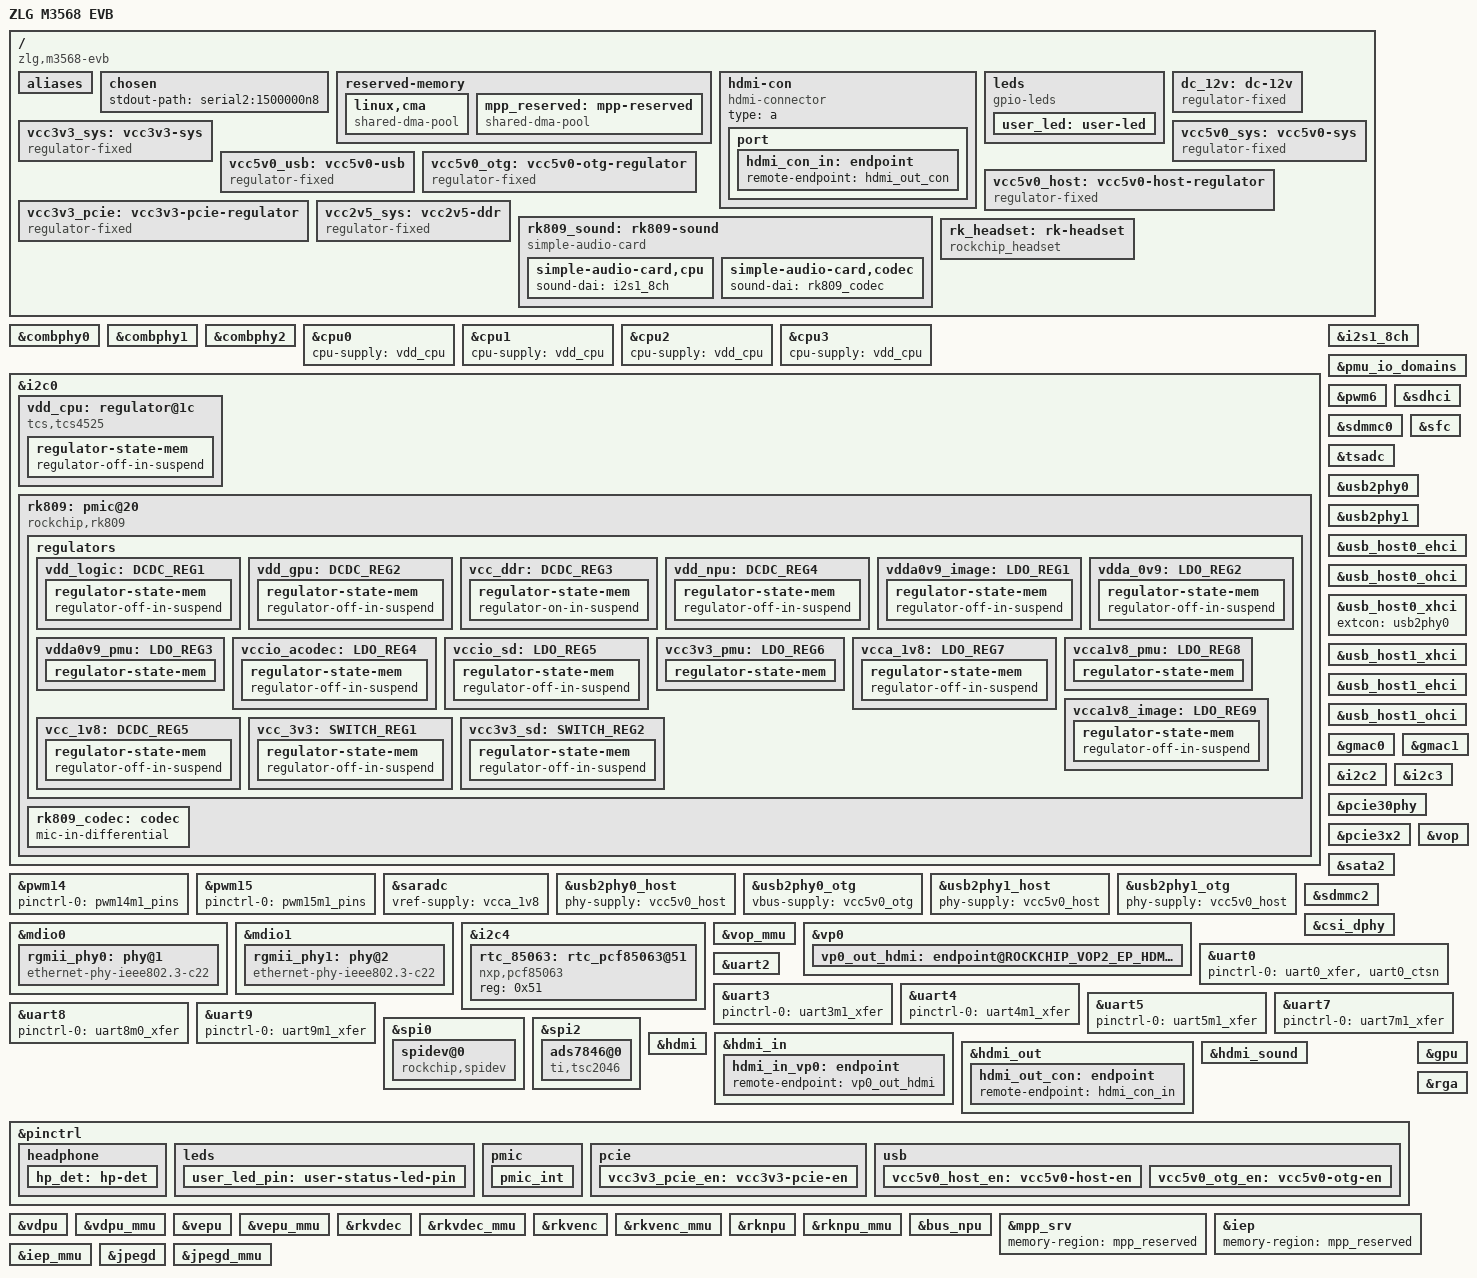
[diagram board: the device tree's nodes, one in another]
// SPDX-License-Identifier: (GPL-2.0+ OR MIT)
/*
 * Copyright (c) 2020 Rockchip Electronics Co., Ltd.
 * Copyright (c) 2025 Lemon1151 <smile1151@foxmail.com>
 *
 */

/dts-v1/;

#include <dt-bindings/gpio/gpio.h>
#include <dt-bindings/pwm/pwm.h>
#include <dt-bindings/leds/common.h>
#include <dt-bindings/input/input.h>
#include <dt-bindings/pinctrl/rockchip.h>
#include <dt-bindings/soc/rockchip,vop2.h>
#include "rk3568.dtsi"
#include "rk3568-vngpu.dtsi"
#include "rk3568-vngpu-rk809.dtsi"

/ {
	model = "ZLG M3568 EVB";
	compatible = "zlg,m3568-evb", "rockchip,rk3568";
	bootargs = "earlycon=uart8250,mmio32,0xfe660000 console=ttyFIQ0";
	
	aliases {
		ethernet0 = &gmac1;
		ethernet1 = &gmac0;
		mmc0 = &sdhci;
		mmc1 = &sdmmc0;
	};

  	chosen: chosen {
    		stdout-path = "serial2:1500000n8";
  	};

	reserved-memory {
		#address-cells = <2>;
		#size-cells = <2>;
		ranges;

		linux,cma {
			compatible = "shared-dma-pool";
			reusable;
			size = <0x0 0x10000000>; /* 256MB */
			linux,cma-default;
		};

		mpp_reserved: mpp-reserved {
			compatible = "shared-dma-pool";
			no-map;
			size = <0x0 0x8000000>; /* 128MB */
		};
	};

	hdmi-con {
		compatible = "hdmi-connector";
		type = "a";

		port {
			hdmi_con_in: endpoint {
				remote-endpoint = <&hdmi_out_con>;
			};
		};
	};

	leds: leds {
		compatible = "gpio-leds";
		user_led: user-led {
			label = "user_led";
			linux,default-trigger = "heartbeat";
			default-state = "on";
			gpios = <&gpio0 RK_PD6 GPIO_ACTIVE_HIGH>;
			pinctrl-names = "default";
			pinctrl-0 = <&user_led_pin>;
		};
	};

	dc_12v: dc-12v {
		compatible = "regulator-fixed";
		regulator-name = "dc_12v";
		regulator-always-on;
		regulator-boot-on;
		regulator-min-microvolt = <12000000>;
		regulator-max-microvolt = <12000000>;
	};

	vcc3v3_sys: vcc3v3-sys {
		compatible = "regulator-fixed";
		regulator-name = "vcc3v3_sys";
		regulator-always-on;
		regulator-boot-on;
		regulator-min-microvolt = <3300000>;
		regulator-max-microvolt = <3300000>;
		vin-supply = <&dc_12v>;
	};

	vcc5v0_sys: vcc5v0-sys {
		compatible = "regulator-fixed";
		regulator-name = "vcc5v0_sys";
		regulator-always-on;
		regulator-boot-on;
		regulator-min-microvolt = <5000000>;
		regulator-max-microvolt = <5000000>;
		vin-supply = <&dc_12v>;
	};

	vcc5v0_usb: vcc5v0-usb {
		compatible = "regulator-fixed";
		regulator-name = "vcc5v0_usb";
		regulator-always-on;
		regulator-boot-on;
		regulator-min-microvolt = <5000000>;
		regulator-max-microvolt = <5000000>;
		vin-supply = <&dc_12v>;
	};

	vcc5v0_host: vcc5v0-host-regulator {
		compatible = "regulator-fixed";
		regulator-name = "vcc5v0_host";
		regulator-boot-on;
		regulator-always-on;
		regulator-min-microvolt = <5000000>;
		regulator-max-microvolt = <5000000>;
		enable-active-high;
		gpio = <&gpio3 RK_PD5 GPIO_ACTIVE_HIGH>;
		vin-supply = <&vcc5v0_usb>;
		pinctrl-names = "default";
		pinctrl-0 = <&vcc5v0_host_en>;
	};

	vcc5v0_otg: vcc5v0-otg-regulator {
		compatible = "regulator-fixed";
		regulator-name = "vcc5v0_otg";
		regulator-min-microvolt = <5000000>;
		regulator-max-microvolt = <5000000>;
		enable-active-high;
		gpio = <&gpio4 RK_PB2 GPIO_ACTIVE_HIGH>;
		vin-supply = <&vcc5v0_usb>;
		pinctrl-names = "default";
		pinctrl-0 = <&vcc5v0_otg_en>;
	};

	vcc3v3_pcie: vcc3v3-pcie-regulator {
    		compatible = "regulator-fixed";
    		regulator-name = "vcc3v3_pcie";
    		regulator-min-microvolt = <3300000>;
    		regulator-max-microvolt = <3300000>;
    		gpio = <&gpio0 RK_PD4 GPIO_ACTIVE_HIGH>;
    		enable-active-high;
    		pinctrl-names = "default";
    		pinctrl-0 = <&vcc3v3_pcie_en>;
    		startup-delay-us = <10000>;
    		vin-supply = <&vcc5v0_sys>;
	};

	vcc2v5_sys: vcc2v5-ddr {
		compatible = "regulator-fixed";
		regulator-name = "vcc2v5-sys";
		regulator-always-on;
		regulator-boot-on;
		regulator-min-microvolt = <2500000>;
		regulator-max-microvolt = <2500000>;
		vin-supply = <&vcc3v3_sys>;
	};
	
	rk809_sound: rk809-sound {
		status = "okay";
		compatible = "simple-audio-card";
		simple-audio-card,format = "i2s";
		simple-audio-card,name = "rockchip,rk809-codec";
		simple-audio-card,mclk-fs = <256>;

		simple-audio-card,cpu {
			sound-dai = <&i2s1_8ch>;
		};
		simple-audio-card,codec {
			sound-dai = <&rk809_codec>;
		};
	};

	rk_headset: rk-headset {
		compatible = "rockchip_headset";
		headset_gpio = <&gpio1 RK_PB2 GPIO_ACTIVE_LOW>;
		pinctrl-names = "default";
		pinctrl-0 = <&hp_det>;
	};
};

&combphy0 {
	status = "okay";
};

&combphy1 {
	status = "okay";
};

&combphy2 {
	status = "okay";
};

&cpu0 {
	cpu-supply = <&vdd_cpu>;
};

&cpu1 {
	cpu-supply = <&vdd_cpu>;
};

&cpu2 {
	cpu-supply = <&vdd_cpu>;
};

&cpu3 {
	cpu-supply = <&vdd_cpu>;
};

&i2c0 {
	status = "okay";

	vdd_cpu: regulator@1c {
		compatible = "tcs,tcs4525";
		reg = <0x1c>;
		fcs,suspend-voltage-selector = <1>;
		regulator-name = "vdd_cpu";
		regulator-min-microvolt = <800000>;
		regulator-max-microvolt = <1150000>;
		regulator-ramp-delay = <2300>;
		regulator-always-on;
		regulator-boot-on;
		vin-supply = <&vcc5v0_sys>;

		regulator-state-mem {
			regulator-off-in-suspend;
		};
	};

	rk809: pmic@20 {
		compatible = "rockchip,rk809";
		reg = <0x20>;
		interrupt-parent = <&gpio0>;
		interrupts = <3 IRQ_TYPE_LEVEL_LOW>;
		#clock-cells = <1>;
		#sound-dai-cells = <0>;
		clock-output-names = "rk808-clkout1", "rk808-clkout2";
		pinctrl-names = "default";
		pinctrl-0 = <&pmic_int>;
		rockchip,system-power-controller;
		wakeup-source;

		vcc1-supply = <&vcc3v3_sys>;
		vcc2-supply = <&vcc3v3_sys>;
		vcc3-supply = <&vcc3v3_sys>;
		vcc4-supply = <&vcc3v3_sys>;
		vcc5-supply = <&vcc3v3_sys>;
		vcc6-supply = <&vcc3v3_sys>;
		vcc7-supply = <&vcc3v3_sys>;
		vcc8-supply = <&vcc3v3_sys>;
		vcc9-supply = <&vcc3v3_sys>;

		regulators {
			vdd_logic: DCDC_REG1 {
				regulator-always-on;
				regulator-boot-on;
				regulator-min-microvolt = <500000>;
				regulator-max-microvolt = <1350000>;
				regulator-init-microvolt = <900000>;
				regulator-ramp-delay = <6001>;
				regulator-initial-mode = <0x2>;
				regulator-name = "vdd_logic";
				regulator-state-mem {
					regulator-off-in-suspend;
				};
			};

			vdd_gpu: DCDC_REG2 {
				regulator-always-on;
				regulator-boot-on;
				regulator-min-microvolt = <500000>;
				regulator-max-microvolt = <1350000>;
				regulator-init-microvolt = <900000>;
				regulator-ramp-delay = <6001>;
				regulator-initial-mode = <0x2>;
				regulator-name = "vdd_gpu";
				regulator-state-mem {
					regulator-off-in-suspend;
				};
			};

			vcc_ddr: DCDC_REG3 {
				regulator-always-on;
				regulator-boot-on;
				regulator-initial-mode = <0x2>;
				regulator-name = "vcc_ddr";
				regulator-state-mem {
					regulator-on-in-suspend;
				};
			};

			vdd_npu: DCDC_REG4 {
				regulator-always-on;
				regulator-boot-on;
				regulator-min-microvolt = <500000>;
				regulator-max-microvolt = <1350000>;
				regulator-init-microvolt = <900000>;
				regulator-ramp-delay = <6001>;
				regulator-initial-mode = <0x2>;
				regulator-name = "vdd_npu";
				regulator-state-mem {
					regulator-off-in-suspend;
				};
			};

			vdda0v9_image: LDO_REG1 {
				regulator-boot-on;
				regulator-always-on;
				regulator-min-microvolt = <900000>;
				regulator-max-microvolt = <900000>;
				regulator-name = "vdda0v9_image";
				regulator-state-mem {
					regulator-off-in-suspend;
				};
			};

			vdda_0v9: LDO_REG2 {
				regulator-always-on;
				regulator-boot-on;
				regulator-min-microvolt = <900000>;
				regulator-max-microvolt = <900000>;
				regulator-name = "vdda_0v9";
				regulator-state-mem {
					regulator-off-in-suspend;
				};
			};

			vdda0v9_pmu: LDO_REG3 {
				regulator-always-on;
				regulator-boot-on;
				regulator-min-microvolt = <900000>;
				regulator-max-microvolt = <900000>;
				regulator-name = "vdda0v9_pmu";
				regulator-state-mem {
					regulator-on-in-suspend;
					regulator-suspend-microvolt = <900000>;
				};
			};

			vccio_acodec: LDO_REG4 {
				regulator-always-on;
				regulator-boot-on;
				regulator-min-microvolt = <3300000>;
				regulator-max-microvolt = <3300000>;
				regulator-name = "vccio_acodec";
				regulator-state-mem {
					regulator-off-in-suspend;
				};
			};

			vccio_sd: LDO_REG5 {
				regulator-always-on;
				regulator-boot-on;
				regulator-min-microvolt = <1800000>;
				regulator-max-microvolt = <3300000>;
				regulator-name = "vccio_sd";
				regulator-state-mem {
					regulator-off-in-suspend;
				};
			};

			vcc3v3_pmu: LDO_REG6 {
				regulator-always-on;
				regulator-boot-on;
				regulator-min-microvolt = <3300000>;
				regulator-max-microvolt = <3300000>;
				regulator-name = "vcc3v3_pmu";
				regulator-state-mem {
					regulator-on-in-suspend;
					regulator-suspend-microvolt = <3300000>;
				};
			};

			vcca_1v8: LDO_REG7 {
				regulator-always-on;
				regulator-boot-on;
				regulator-min-microvolt = <1800000>;
				regulator-max-microvolt = <1800000>;
				regulator-name = "vcca_1v8";
				regulator-state-mem {
					regulator-off-in-suspend;
				};
			};

			vcca1v8_pmu: LDO_REG8 {
				regulator-always-on;
				regulator-boot-on;
				regulator-min-microvolt = <1800000>;
				regulator-max-microvolt = <1800000>;
				regulator-name = "vcca1v8_pmu";
				regulator-state-mem {
					regulator-on-in-suspend;
					regulator-suspend-microvolt = <1800000>;
				};
			};

			vcca1v8_image: LDO_REG9 {
				regulator-always-on;
				regulator-boot-on;
				regulator-min-microvolt = <1800000>;
				regulator-max-microvolt = <1800000>;
				regulator-name = "vcca1v8_image";
				regulator-state-mem {
					regulator-off-in-suspend;
				};
			};

			vcc_1v8: DCDC_REG5 {
				regulator-always-on;
				regulator-boot-on;
				regulator-min-microvolt = <1800000>;
				regulator-max-microvolt = <1800000>;
				regulator-name = "vcc_1v8";
				regulator-state-mem {
					regulator-off-in-suspend;
				};
			};

			vcc_3v3: SWITCH_REG1 {
				regulator-always-on;
				regulator-boot-on;
				regulator-name = "vcc_3v3";
				regulator-state-mem {
					regulator-off-in-suspend;
				};
			};

			vcc3v3_sd: SWITCH_REG2 {
				regulator-always-on;
				regulator-boot-on;
				regulator-name = "vcc3v3_sd";
				regulator-state-mem {
					regulator-off-in-suspend;
				};
			};
		};
		
		rk809_codec: codec {
			mic-in-differential;
			#sound-dai-cells = <0>;
		};
	};
};

&i2s1_8ch {
	status = "okay";
	pinctrl-names = "default";
	pinctrl-0 = <&i2s1m0_sclktx
		     &i2s1m0_lrcktx
		     &i2s1m0_sdi0
		     &i2s1m0_sdo0>;
	rockchip,trcm-sync-tx-only;
};

&pmu_io_domains {
	status = "okay";
	pmuio2-supply = <&vcc3v3_pmu>;
	vccio1-supply = <&vccio_acodec>;
	vccio3-supply = <&vccio_sd>;
	vccio4-supply = <&vcc_3v3>;
	vccio5-supply = <&vcc_3v3>;
	vccio6-supply = <&vcc_3v3>;
	vccio7-supply = <&vcc_3v3>;
};

&pwm6 {
	status = "okay";
};

&pwm14 {
	pinctrl-0 = <&pwm14m1_pins>;
	status = "okay";
};

&pwm15 {
	pinctrl-0 = <&pwm15m1_pins>;
	status = "okay";
};

&saradc {
	status = "okay";
	vref-supply = <&vcca_1v8>;
};

&sdhci {
	bus-width = <8>;
	supports-emmc;
	non-removable;
	max-frequency = <200000000>;
	status = "okay";
};

&sdmmc0 {
	max-frequency = <150000000>;
	supports-sd;
	bus-width = <4>;
	cap-mmc-highspeed;
	cap-sd-highspeed;
	disable-wp;
	sd-uhs-sdr104;
	vmmc-supply = <&vcc3v3_sd>;
	vqmmc-supply = <&vccio_sd>;
	pinctrl-names = "default";
	pinctrl-0 = <&sdmmc0_bus4 &sdmmc0_clk &sdmmc0_cmd &sdmmc0_det>;
	status = "okay";
};

&sfc {
	status = "okay";
};

&tsadc {
	status = "okay";
};

&usb2phy0_host {
	phy-supply = <&vcc5v0_host>;
	status = "okay";
};

&usb2phy0_otg {
	vbus-supply = <&vcc5v0_otg>;
	status = "okay";
};

&usb2phy1_host {
	phy-supply = <&vcc5v0_host>;
	status = "okay";
};

&usb2phy1_otg {
	phy-supply = <&vcc5v0_host>;
	status = "okay";
};

&usb2phy0 {
	status = "okay";
};

&usb2phy1 {
	status = "okay";
};

&usb_host0_ehci {
	status = "okay";
};

&usb_host0_ohci {
	status = "okay";
};

&usb_host0_xhci {
	extcon = <&usb2phy0>;
	status = "okay";
};

&usb_host1_xhci {
	status = "okay";
};

&usb_host1_ehci {
	status = "okay";
};

&usb_host1_ohci {
	status = "okay";
};

&gmac0 {
	phy-mode = "rgmii";
	clock_in_out = "output";

	snps,reset-gpio = <&gpio1 RK_PB0 GPIO_ACTIVE_LOW>;
	snps,reset-active-low;
	/* Reset time is 20ms, 100ms for rtl8211f */
	snps,reset-delays-us = <0 20000 100000>;

	assigned-clocks = <&cru SCLK_GMAC0_RX_TX>, <&cru SCLK_GMAC0>;
	assigned-clock-parents = <&cru SCLK_GMAC0_RGMII_SPEED>, <&cru CLK_MAC0_2TOP>;
	assigned-clock-rates = <0>, <125000000>;

	pinctrl-names = "default";
	pinctrl-0 = <&gmac0_miim
		     &gmac0_tx_bus2
		     &gmac0_rx_bus2
		     &gmac0_rgmii_clk
		     &gmac0_rgmii_bus>;

	tx_delay = <0x3c>;
	rx_delay = <0x2f>;

	phy-handle = <&rgmii_phy0>;
	status = "okay";
};

&gmac1 {
	phy-mode = "rgmii";
	clock_in_out = "output";

	snps,reset-gpio = <&gpio1 RK_PB1 GPIO_ACTIVE_LOW>;
	snps,reset-active-low;
	/* Reset time is 20ms, 100ms for rtl8211f */
	snps,reset-delays-us = <0 20000 100000>;

	assigned-clocks = <&cru SCLK_GMAC1_RX_TX>, <&cru SCLK_GMAC1>;
	assigned-clock-parents = <&cru SCLK_GMAC1_RGMII_SPEED>, <&cru CLK_MAC1_2TOP>;
	assigned-clock-rates = <0>, <125000000>;

	pinctrl-names = "default";
	pinctrl-0 = <&gmac1m1_miim
		     &gmac1m1_tx_bus2
		     &gmac1m1_rx_bus2
		     &gmac1m1_rgmii_clk
		     &gmac1m1_rgmii_bus>;

	tx_delay = <0x4f>;
	rx_delay = <0x26>;

	phy-handle = <&rgmii_phy1>;
	status = "okay";
};

&mdio0 {
	rgmii_phy0: phy@1 {
		compatible = "ethernet-phy-ieee802.3-c22";
		reg = <0x1>;

		/* ti,dp83867 gphy */
		ti,rx-internal-delay = <0x8>;
		ti,tx-internal-delay = <0xa>;
		ti,fifo-depth = <0X01>;
	};
};

&mdio1 {
	rgmii_phy1: phy@2 {
		compatible = "ethernet-phy-ieee802.3-c22";
		reg = <0x2>;

		/* ti,dp83867 gphy */
		ti,rx-internal-delay = <0X08>;
		ti,tx-internal-delay = <0X0a>;
		ti,fifo-depth = <0X01>;
	};
};

&i2c2 {
	status = "okay";
};

&i2c3 {
	clock-frequency = <400000>;
	pinctrl-0 = <&i2c3m1_xfer>;
	status = "okay";
};

&i2c4 {
	clock-frequency = <400000>;
	pinctrl-0 = <&i2c4m1_xfer>;
	status = "okay";
	
	rtc_85063: rtc_pcf85063@51 {
		compatible = "nxp,pcf85063";
		reg = <0x51>;
	};
};

&pcie30phy {
	status = "okay";
};

&pcie3x2 {
    	reset-gpios = <&gpio0 RK_PB7 GPIO_ACTIVE_HIGH>;  // GPIO0_B7
    	vpcie3v3-supply = <&vcc3v3_pcie>;
    	bus-scan-delay-ms = <2000>;
    	status = "okay";
};

&sata2 {
	status = "okay";
};

&sdmmc2 {
	max-frequency = <150000000>;
	supports-sdio;
	supports-sd;
	bus-width = <4>;
	disable-wp;
	cap-sd-highspeed;
	cap-sdio-irq;
	keep-power-in-suspend;
	//mmc-pwrseq = <&sdio_pwrseq>;
	non-removable;
	pinctrl-names = "default";
	pinctrl-0 = <&sdmmc2m0_bus4 &sdmmc2m0_cmd &sdmmc2m0_clk>;
	//sd-uhs-sdr104;
	status = "okay";
};

&csi_dphy {
	status = "okay";
};

&vop {
	status = "okay";
	assigned-clocks = <&cru DCLK_VOP0>, <&cru DCLK_VOP1>;
	assigned-clock-parents = <&pmucru PLL_HPLL>, <&cru PLL_VPLL>;
};

&vop_mmu {
	status = "okay";
};

&vp0 {
	vp0_out_hdmi: endpoint@ROCKCHIP_VOP2_EP_HDMI0 {
		reg = <ROCKCHIP_VOP2_EP_HDMI0>;
		remote-endpoint = <&hdmi_in_vp0>;
	};
};

&uart0 {
	status = "okay";
	pinctrl-names = "default";
	pinctrl-0 = <&uart0_xfer &uart0_ctsn>;
};

&uart2 {
	status = "okay";
};

&uart3 {
	status = "okay";
	pinctrl-names = "default";
	pinctrl-0 = <&uart3m1_xfer>;
};

&uart4 {
	status = "okay";
	pinctrl-names = "default";
	pinctrl-0 = <&uart4m1_xfer>;
};

&uart5 {
	status = "okay";
	pinctrl-names = "default";
	pinctrl-0 = <&uart5m1_xfer>;
};

&uart7 {	
	pinctrl-names = "default";
	pinctrl-0 = <&uart7m1_xfer>;
	status = "okay";
};

&uart8 {
	status = "okay";
	pinctrl-names = "default";
	pinctrl-0 = <&uart8m0_xfer>;
};

&uart9 {
	status = "okay";
	pinctrl-names = "default";
	pinctrl-0 = <&uart9m1_xfer>;
};

&spi0 {
	pinctrl-names = "default";
	max-freq = <48000000>;
	pinctrl-0 = <&spi0m1_cs0 &spi0m1_pins>;
	status = "okay";
	spidev@0 {
		#address-cells = <1>;
		#size-cells = <1>;
		compatible = "rockchip,spidev";
		spi-max-frequency = <120000000>;
		reg = <0>;
	};   
};

&spi2 {
	status = "okay";
	max-freq = <48000000>;
	pinctrl-names = "default";
	pinctrl-0 = <&spi2m1_pins &spi2m1_cs0 &spi2m1_cs1>;
	ads7846@0 {
		compatible = "ti,tsc2046";
		reg = <0 1>;
		interrupt-parent = <&gpio3>;
		interrupts = <RK_PB4 IRQ_TYPE_LEVEL_LOW>;
		pendown-gpio = <&gpio3 RK_PB4 GPIO_ACTIVE_LOW>;
		spi-cpol;
		spi-max-frequency = <1500000>;
		ti,keep-vref-on;
	};

	ads7846@0 {
		compatible = "ti,tsc2046";
		reg = <0 1>;
		interrupt-parent = <&gpio3>;
		interrupts = <RK_PB0 IRQ_TYPE_LEVEL_LOW>;
		pendown-gpio = <&gpio3 RK_PB0 GPIO_ACTIVE_LOW>;
		spi-cpol;
		spi-max-frequency = <1500000>;
		ti,keep-vref-on;
	};
};

&hdmi {
	avdd-0v9-supply = <&vdda0v9_image>;
	avdd-1v8-supply = <&vcca1v8_image>;
	status = "okay";
};

&hdmi_in {
	hdmi_in_vp0: endpoint {
		remote-endpoint = <&vp0_out_hdmi>;
	};
};

&hdmi_out {
	hdmi_out_con: endpoint {
		remote-endpoint = <&hdmi_con_in>;
	};
};

&hdmi_sound {
	status = "okay";
};

&pinctrl {
	headphone {
		hp_det: hp-det {
			rockchip,pins = <1 RK_PB2 RK_FUNC_GPIO &pcfg_pull_down>;
		};
	};

	leds {
		user_led_pin: user-status-led-pin {
			rockchip,pins = <0 RK_PD6 RK_FUNC_GPIO &pcfg_pull_none>;
		};
	};

	pmic {
		pmic_int: pmic_int {
			rockchip,pins =
				<0 RK_PA3 RK_FUNC_GPIO &pcfg_pull_up>;
		};
	};

	pcie {
		vcc3v3_pcie_en: vcc3v3-pcie-en {
			rockchip,pins = <0 RK_PD4 RK_FUNC_GPIO &pcfg_pull_none>;
		};
	};

	usb {
		vcc5v0_host_en: vcc5v0-host-en {
			rockchip,pins = <3 RK_PD5 RK_FUNC_GPIO &pcfg_pull_none>;
		};

		vcc5v0_otg_en: vcc5v0-otg-en {
			rockchip,pins = <4 RK_PB2 RK_FUNC_GPIO &pcfg_pull_none>;
		};
	};
};

&gpu {
	operating-points-v2 = <&gpu_opp_table>;
	power-off-delay-ms = <20>;
	mali-supply = <&vdd_gpu>;
	status = "okay";
};

&vdpu {
	status = "okay";
};

&vdpu_mmu {
	status = "okay";
};

&rga {
	status = "okay";
};

&vepu {
	status = "okay";
};

&vepu_mmu {
	status = "okay";
};

&vop {
	status = "okay";
};

&rkvdec {
	operating-points-v2 = <&rkvdec_opp_table>;
	memory-region = <&mpp_reserved>;
	vdec-supply = <&vdd_logic>;
	status = "okay";

	/* 补全复位信号名称 */
	resets = <&cru SRST_A_RKVDEC>, <&cru SRST_H_RKVDEC>,
			 <&cru SRST_RKVDEC_CA>, <&cru SRST_RKVDEC_CORE>,
			 <&cru SRST_RKVDEC_HEVC_CA>,
			 <&cru SRST_A_VPU_NIU>, <&cru SRST_H_VPU_NIU>;

	reset-names = "video_a", "video_h", "video_cabac",
					"video_core", "video_hevc_cabac",
					"shared_niu_a", "shared_niu_h";
};

&rkvdec_mmu {
	status = "okay";
};

&rkvenc {
	operating-points-v2 = <&rkvenc_opp_table>;
	venc-supply = <&vdd_logic>;
	status = "okay";
};

&rkvenc_mmu {
	status = "okay";
};

&rknpu {
	operating-points-v2 = <&npu_opp_table>;
	rknpu-supply = <&vdd_npu>;
	status = "okay";
};

&rknpu_mmu {
	status = "okay";
};

&bus_npu {
	operating-points-v2 = <&bus_npu_opp_table>;
	bus-supply = <&vdd_logic>;
	pvtm-supply = <&vdd_cpu>;
	status = "okay";
};

&mpp_srv {
	status = "okay";
	memory-region = <&mpp_reserved>;
};

&iep {
	status = "okay";
	memory-region = <&mpp_reserved>;
};

&iep_mmu {
	status = "okay";
};

&jpegd {
	status = "okay";
};

&jpegd_mmu {
	status = "okay";
};
